# GD32E25x register map
File version: 1.0
CPU: CM23 r1p0, little endian, no MPU, no FPU, 2 interrupt priority bits
Registers are 32-bit, read-write, reset 0x0 unless marked. A register's access mark holds for its fields unless they carry their own. Offsets are from the block's base; [hi:lo] are bit positions; {n}, {i} and the like mark numbered series.

## TIMER0 — Advanced-timers
Base 0x40012C00
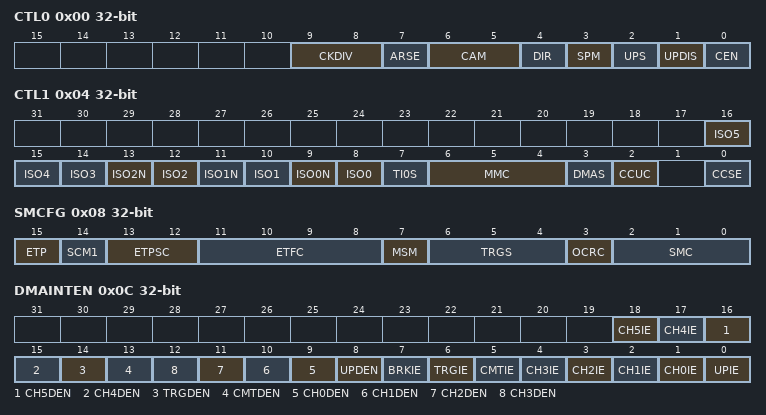
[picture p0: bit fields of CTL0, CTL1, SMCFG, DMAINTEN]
0x00 CTL0 — control register 0
  [9:8] CKDIV — Clock division
  [7] ARSE — Auto-reload preload enable
  [6:5] CAM — Center-aligned mode selection
  [4] DIR — Direction
  [3] SPM — One-pulse mode
  [2] UPS — Update request source
  [1] UPDIS — Update disable
  [0] CEN — Counter enable
0x04 CTL1 — control register 1
  [16] ISO5 — Idle state of channel 5 output
  [15] ISO4 — Idle state of channel 4 output
  [2n+8] ISO{n} (n=0..3) — Idle state of channel {n} output
  [13] ISO2N — Idle state of channel 2 complementary output
  [11] ISO1N — Idle state of channel 1 complementary output
  [9] ISO0N — Idle state of channel 0 complementary output
  [7] TI0S — Channel 0 trigger input selection
  [6:4] MMC — Master mode control
  [3] DMAS — DMA request source selection
  [2] CCUC — Commutation control shadow register update control
  [0] CCSE — Commutation control shadow enable
0x08 SMCFG — slave mode configuration register
  [15] ETP — External trigger polarity
  [14] SCM1 — Part of SMC for enable External clock mode1
  [13:12] ETPSC — External trigger prescaler
  [11:8] ETFC — External trigger filter
  [7] MSM — Master/Slave mode
  [6:4] TRGS — Trigger selection
  [3] OCRC — Trigger selection
  [2:0] SMC — Slave mode selection
0x0C DMAINTEN — DMA/Interrupt enable register
  [18] CH5IE — Channel 5 capture/compare interrupt enable
  [17] CH4IE — Channel 4 capture/compare interrupt enable
  [16] CH5DEN — Channel 5 capture/compare DMA request enable
  [15] CH4DEN — Channel 4 capture/compare DMA request enable
  [14] TRGDEN — Trigger DMA request enable
  [13] CMTDEN — Commutation DMA request enable
  [n+9] CH{n}DEN (n=0..3) — Capture/Compare {n} DMA request enable
  [8] UPDEN — Update DMA request enable
  [7] BRKIE — Break interrupt enable
  [6] TRGIE — Trigger interrupt enable
  [5] CMTIE — COM interrupt enable
  [n+1] CH{n}IE (n=0..3) — Capture/Compare {n} interrupt enable
  [0] UPIE — Update interrupt enable
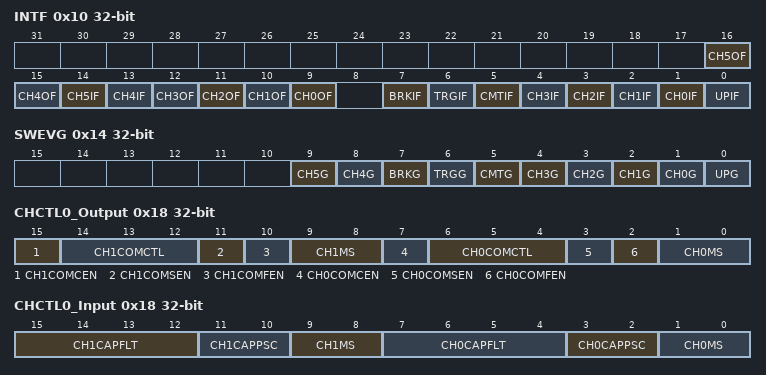
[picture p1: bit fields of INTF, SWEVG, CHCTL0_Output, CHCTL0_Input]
0x10 INTF — status register
  [16] CH5OF — Channel 5 over capture flag
  [15] CH4OF — Channel 4 over capture flag
  [14] CH5IF — Channel 5 capture/compare interrupt flag
  [13] CH4IF — Channel 4 capture/compare interrupt flag
  [n+9] CH{n}OF (n=0..3) — Channel {n} over capture flag
  [7] BRKIF — Break interrupt flag
  [6] TRGIF — Trigger interrupt flag
  [5] CMTIF — COM interrupt flag
  [4] CH3IF — Capture/Compare 3 interrupt flag
  [3] CH2IF — Capture/Compare 2 interrupt flag
  [2] CH1IF — Capture/Compare 1 interrupt flag
  [1] CH0IF — Capture/compare 0 interrupt flag
  [0] UPIF — Update interrupt flag
0x14 SWEVG wo — Software event generation register
  [9] CH5G — Channel 3's capture or compare event generation
  [8] CH4G — Channel 2's capture or compare event generation
  [7] BRKG — Break event generation
  [6] TRGG — Trigger event generation
  [5] CMTG — Channel commutation event generation
  [n+1] CH{n}G (n=0..3) — Channel {n}'s capture or compare event generation
  [0] UPG — Update event generation
0x18 CHCTL0_Output — capture/compare mode register (output mode)
  [15] CH1COMCEN — Channel 1 output compare clear enable
  [14:12] CH1COMCTL — Channel 1 compare output control
  [11] CH1COMSEN — Channel 1 output compare shadow enable
  [10] CH1COMFEN — Channel 1 output compare fast enable
  [9:8] CH1MS — Channel 1 mode selection
  [7] CH0COMCEN — Channel 0 output compare clear enable
  [6:4] CH0COMCTL — Channel 0 compare output control
  [3] CH0COMSEN — Channel 0 compare output shadow enable
  [2] CH0COMFEN — Channel 0 output compare fast enable
  [1:0] CH0MS — Channel 0 I/O mode selection
0x18 CHCTL0_Input (alternate view of CHCTL0_Output) — capture/compare mode register 0 (input mode)
  [15:12] CH1CAPFLT — Channel 1 input capture filter control
  [11:10] CH1CAPPSC — Channel 1 input capture prescaler
  [9:8] CH1MS — Channel 1 mode selection
  [7:4] CH0CAPFLT — Channel 0 input capture filter control
  [3:2] CH0CAPPSC — Channel 0 input capture prescaler
  [1:0] CH0MS — Channel 0 mode selection
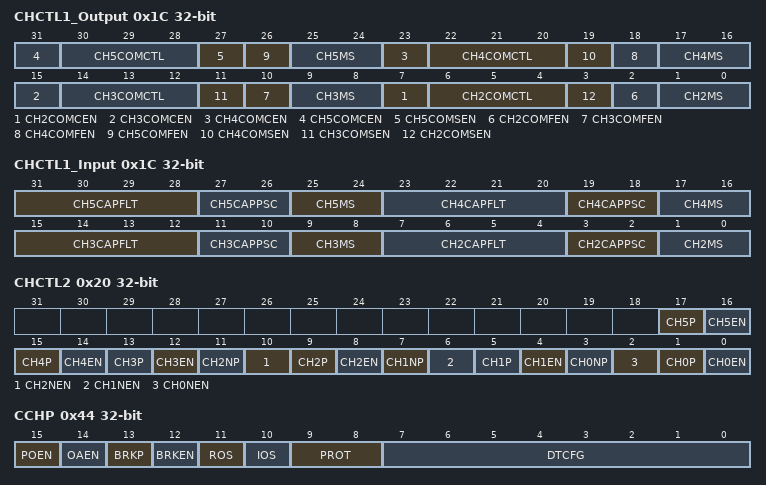
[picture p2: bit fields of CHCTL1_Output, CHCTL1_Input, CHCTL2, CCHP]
0x1C CHCTL1_Output — capture/compare mode register (output mode)
  [8n-9] CH{n}COMCEN (n=2..5) — Channel {n} output compare clear enable
  [8n-10:8n-12] CH{n}COMCTL (n=2..5) — Channel {n} compare output control
  [27] CH5COMSEN — Channel 5 output compare shadow enable
  [8n-14] CH{n}COMFEN (n=2..5) — Channel {n} output compare fast enable
  [25:24] CH5MS — Channel 5 mode selection
  [19] CH4COMSEN — Channel 4 compare output shadow enable
  [17:16] CH4MS — Channel 4 I/O mode selection
  [11] CH3COMSEN — Channel 3 output compare shadow enable
  [9:8] CH3MS — Channel 3 mode selection
  [3] CH2COMSEN — Channel 2 compare output shadow enable
  [1:0] CH2MS — Channel 2 I/O mode selection
0x1C CHCTL1_Input (alternate view of CHCTL1_Output) — capture/compare mode register 1 (input mode)
  [31:28] CH5CAPFLT — Channel 4 input capture filter control
  [27:26] CH5CAPPSC — Channel 4 input capture prescaler
  [25:24] CH5MS — Channel 4 mode selection
  [23:20] CH4CAPFLT — Input capture 3 filter
  [19:18] CH4CAPPSC — Input capture 3 prescaler
  [17:16] CH4MS — Capture/compare 3 selection
  [15:12] CH3CAPFLT — Channel 3 input capture filter control
  [11:10] CH3CAPPSC — Channel 3 input capture prescaler
  [9:8] CH3MS — Channel 3 mode selection
  [7:4] CH2CAPFLT — Input capture 2 filter
  [3:2] CH2CAPPSC — Input capture 2 prescaler
  [1:0] CH2MS — Capture/compare 2 selection
0x20 CHCTL2 — capture/compare enable register
  [17] CH5P — Capture/Compare 5 output Polarity
  [16] CH5EN — Capture/Compare 5 output enable
  [15] CH4P — Capture/Compare 4 output Polarity
  [14] CH4EN — Capture/Compare 4 output enable
  [4n+1] CH{n}P (n=0..3) — Capture/Compare {n} output Polarity
  [12] CH3EN — Capture/Compare 3 output enable
  [11] CH2NP — Capture/Compare 2 output Polarity
  [10] CH2NEN — Capture/Compare 2 complementary output enable
  [8] CH2EN — Capture/Compare 2 output enable
  [7] CH1NP — Capture/Compare 1 output Polarity
  [6] CH1NEN — Capture/Compare 1 complementary output enable
  [4] CH1EN — Capture/Compare 1 output enable
  [3] CH0NP — Capture/Compare 0 output Polarity
  [2] CH0NEN — Capture/Compare 0 complementary output enable
  [0] CH0EN — Capture/Compare 1 output enable
0x24 CNT — counter
  [15:0] CNT — counter value
0x28 PSC — prescaler
  [15:0] PSC — Prescaler value
0x2C CAR — auto-reload register
  [15:0] CARL — Counter auto reload value
0x30 CREP — repetition counter register
  [7:0] CREP — Repetition counter value
{0x34+4i} CH{i}CV (i=0..3) — capture/compare register {i}
  [15:0] CH{i}VAL — Capture/Compare {i} value
0x44 CCHP — channel complementary protection register
  [15] POEN — Primary output enable
  [14] OAEN — Automatic output enable
  [13] BRKP — Break polarity
  [12] BRKEN — Break enable
  [11] ROS — Off-state selection for Run mode
  [10] IOS — Off-state selection for Idle mode
  [9:8] PROT — Lock configuration
  [7:0] DTCFG — Dead-time generator setup
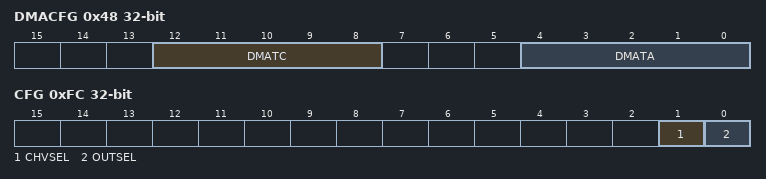
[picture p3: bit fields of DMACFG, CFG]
0x48 DMACFG — DMA configuration register
  [12:8] DMATC — DMA transfer count
  [4:0] DMATA — DMA transfer access start address
0x4C DMATB — DMA transfer buffer register
  [15:0] DMATB — DMA transfer buffer
0x50 CH4CV — capture/compare register 4
  [15:0] CH4VAL — Capture/Compare 4 value
0x54 CH5CV — capture/compare register 5
  [15:0] CH5VAL — Capture/Compare 5 value
0xFC CFG — Configuration register
  [1] CHVSEL — Write CHxVAL register selection
  [0] OUTSEL — The output value selection
